# ATtiny1634 device description
Architecture: AVR8; Family: tinyAVR
Registers are 8-bit, access not given, no defined reset value unless marked. A register's access mark holds for its fields unless they carry their own. Offsets are from the block's base; [hi:lo] are bit positions.

## AC — Analog Comparator
Instances: AC 0x00
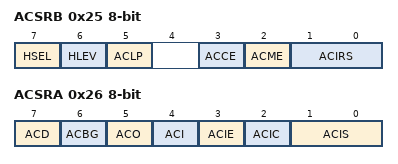
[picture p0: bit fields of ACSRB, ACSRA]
0x25 ACSRB — Analog Comparator Control And Status Register B
  [7] HSEL — Hysteresis Select
  [6] HLEV — Hysteresis Level
  [5] ACLP
  [3] ACCE
  [2] ACME — Analog Comparator Multiplexer Enable
  [1:0] ACIRS
0x26 ACSRA — Analog Comparator Control And Status Register A
  [7] ACD — Analog Comparator Disable
  [6] ACBG — Analog Comparator Bandgap Select
  [5] ACO — Analog Compare Output
  [4] ACI — Analog Comparator Interrupt Flag
  [3] ACIE — Analog Comparator Interrupt Enable
  [2] ACIC — Analog Comparator Input Capture Enable
  [1:0] ACIS — Analog Comparator Interrupt Mode Select bits
    0=Interrupt on Toggle; 2=Interrupt on Falling Edge; 3=Interrupt on Rising Edge

## EEPROM
Instances: EEPROM 0x00
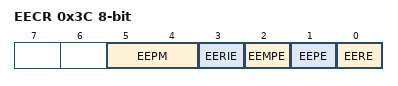
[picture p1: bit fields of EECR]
0x3C EECR — EEPROM Control Register
  [5:4] EEPM — EEPROM Programming Mode Bits
    0=Erase and Write in one operation; 1=Erase Only; 2=Write Only
  [3] EERIE — EEProm Ready Interrupt Enable
  [2] EEMPE — EEPROM Master Write Enable
  [1] EEPE — EEPROM Write Enable
  [0] EERE — EEPROM Read Enable
0x3D EEDR — EEPROM Data Register
0x3E EEAR 16-bit bits used 8:0 — EEPROM Read/Write Access

## TC1 (TC16 module) — Timer/Counter, 16-bit
Instances: TC1 0x00
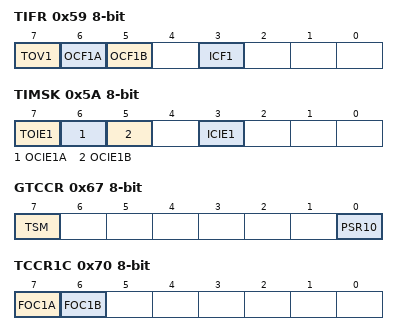
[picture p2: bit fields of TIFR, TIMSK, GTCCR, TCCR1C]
0x59 TIFR — Timer/Counter Interrupt Flag register
  [7] TOV1 — Timer/Counter1 Overflow Flag
  [6] OCF1A — Output Compare Flag 1A
  [5] OCF1B — Output Compare Flag 1B
  [3] ICF1 — Input Capture Flag 1
0x5A TIMSK — Timer/Counter Interrupt Mask Register
  [7] TOIE1 — Timer/Counter1 Overflow Interrupt Enable
  [6] OCIE1A — Timer/Counter1 Output CompareA Match Interrupt Enable
  [5] OCIE1B — Timer/Counter1 Output CompareB Match Interrupt Enable
  [3] ICIE1 — Timer/Counter1 Input Capture Interrupt Enable
0x67 GTCCR — General Timer/Counter Control Register
  [7] TSM — Timer/Counter Synchronization Mode
  [0] PSR10 — Prescaler Reset Timer/Counter1 and Timer/Counter0
0x68 ICR1 16-bit — Timer/Counter1 Input Capture Register Bytes
0x6A OCR1B 16-bit — Timer/Counter1 Output Compare Register Bytes
0x6C OCR1A 16-bit — Timer/Counter1 Output Compare Register Bytes
0x6E TCNT1 16-bit — Timer/Counter1 Bytes
0x70 TCCR1C — Timer/Counter1 Control Register C
  [7] FOC1A — Force Output Compare for Channel A
  [6] FOC1B — Force Output Compare for Channel B
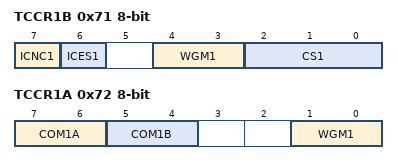
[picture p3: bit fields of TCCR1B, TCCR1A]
0x71 TCCR1B — Timer/Counter1 Control Register B
  [7] ICNC1 — Input Capture 1 Noise Canceler
  [6] ICES1 — Input Capture 1 Edge Select
  [4:3] WGM1 (bit 2 of the value upward) — Waveform Generation Mode Bits
  [2:0] CS1 — Clock Select1 bits
    0=No Clock Source (Stopped); 1=Running, No Prescaling; 2=Running, CLK/8; 3=Running, CLK/64; 4=Running, CLK/256; 5=Running, CLK/1024; 6=Running, ExtClk Tx Falling Edge; 7=Running, ExtClk Tx Rising Edge
0x72 TCCR1A — Timer/Counter1 Control Register A
  [7:6] COM1A — Compare Output Mode 1A, bits
  [5:4] COM1B — Compare Output Mode 1B, bits
  [1:0] WGM1 — Pulse Width Modulator Select Bits

## TC0 (TC8 module) — Timer/Counter, 8-bit
Instances: TC0 0x00
0x37 OCR0B — Timer/Counter0 Output Compare Register
0x38 OCR0A — Timer/Counter0 Output Compare Register
0x39 TCNT0 — Timer/Counter0
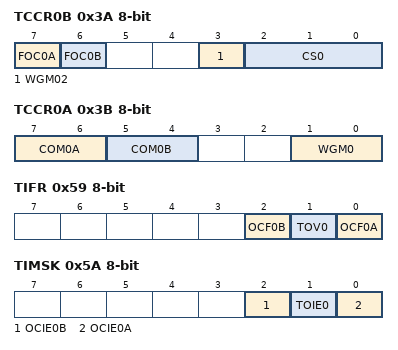
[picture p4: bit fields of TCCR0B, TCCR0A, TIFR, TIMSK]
0x3A TCCR0B — Timer/Counter Control Register B
  [7] FOC0A — Force Output Compare B
  [6] FOC0B — Force Output Compare B
  [3] WGM02
  [2:0] CS0 — Clock Select
    0=No Clock Source (Stopped); 1=Running, No Prescaling; 2=Running, CLK/8; 3=Running, CLK/64; 4=Running, CLK/256; 5=Running, CLK/1024; 6=Running, ExtClk Tx Falling Edge; 7=Running, ExtClk Tx Rising Edge
0x3B TCCR0A — Timer/Counter Control Register A
  [7:6] COM0A — Compare Match Output A Mode
  [5:4] COM0B — Compare Match Output B Mode
  [1:0] WGM0 — Waveform Generation Mode
0x59 TIFR — Timer/Counter Interrupt Flag register
  [2] OCF0B — Timer/Counter0 Output Compare Flag 0B
  [1] TOV0 — Timer/Counter0 Overflow Flag
  [0] OCF0A — Timer/Counter0 Output Compare Flag 0A
0x5A TIMSK — Timer/Counter Interrupt Mask Register
  [2] OCIE0B — Timer/Counter0 Output Compare Match B Interrupt Enable
  [1] TOIE0 — Timer/Counter0 Overflow Interrupt Enable
  [0] OCIE0A — Timer/Counter0 Output Compare Match A Interrupt Enable
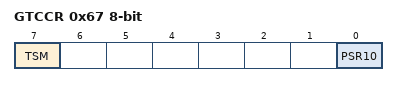
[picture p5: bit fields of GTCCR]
0x67 GTCCR — General Timer/Counter Control Register
  [7] TSM — Timer/Counter Synchronization Mode
  [0] PSR10 — Prescaler Reset Timer/Counter1 and Timer/Counter0
